# LPC13Uxx register map
File version: 1
CPU: CM3 r2p1, little endian, no MPU, no FPU, 0x3 interrupt priority bits, 0x0 interrupts
Registers are 32-bit, read-write, reset 0x0 unless marked. A register's access mark holds for its fields unless they carry their own. Offsets are from the block's base; [hi:lo] are bit positions; {n}, {i} and the like mark numbered series; 'fields as' and 'values as' point back to an identical list.

## RITIMER — Repetitive Interrupt Timer (RI timer)
Base 0x40064000
0x00 COMPVAL reset 0xFFFFFFFF — Compare value LSB register. Holds the 32 LSBs of the compare value.
  [31:0] RICOMP — Compare register. Holds the 32 LSBs of the compare value which is compared to the counter.
0x04 MASK — Mask LSB register. This register holds the 32 LSB s of the mask value. A one written to any bit will force a compare on the corresponding bit of the counter and compare register.
  [31:0] RIMASK — Mask register. This register holds the 32 LSBs of the mask value. A one written to any bit overrides the result of the comparison for the corresponding bit of the counter and compare register (causes the comparison of the register bits to be always true).
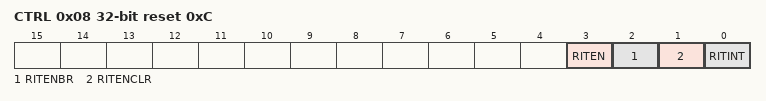
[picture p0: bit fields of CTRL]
0x08 CTRL reset 0xC — Control register.
  [3] RITEN — Timer enable.
    1=TIMER_ENABLED (Timer enabled. This can be overruled by a debug halt if enabled in bit 2.); 0=TIMER_DISABLED_
  [2] RITENBR — Timer enable for debug
    1=HALT_ON_DEBUG (The timer is halted when the processor is halted for debugging.); 0=NO_EFFECT_ON_DEBUG (Debug has no effect on the timer operation.)
  [1] RITENCLR — Timer enable clear
    1=CLEAR_ON_O (The timer will be cleared to 0 whenever the counter value equals the masked compare value specified by the contents of COMPVAL/COMPVAL_H and MASK/MASK_H registers. This will occur on the same clock that sets the interrupt flag.); 0=NOT_CLEAR_ON_0 (The timer will not be cleared to 0.)
  [0] RITINT — Interrupt flag
    1=MASK (This bit is set to 1 by hardware whenever the counter value equals the masked compare value specified by the contents of RICOMPVAL and RIMASK registers. Writing a 1 to this bit will clear it to 0. Writing a 0 has no effect.); 0=NO_MASK (The counter value does not equal the masked compare value.)
0x0C COUNTER — Counter LSB register. 32 LSBs of the counter.
  [31:0] RICOUNTER — 32 LSBs of the up counter. Counts continuously unless RITEN bit in CTRL register is cleared or debug mode is entered (if enabled by the RITNEBR bit in RICTRL). Can be loaded to any value in software.
0x10 COMPVAL_H reset 0xFFFF — Compare value MSB register. Holds the 16 MSBs of the compare value.
  [15:0] RICOMP — Compare value MSB register. Holds the 16 MSBs of the compare value which is compared to the counter.
0x14 MASK_H — Mask MSB register. This register holds the 16 MSBs of the mask value. A one written to any bit will force a compare on the corresponding bit of the counter and compare register.
  [15:0] RIMASK — Mask register. This register holds the 16 MSBs of the mask value. A one written to any bit overrides the result of the comparison for the corresponding bit of the counter and compare register (causes the comparison of the register bits to be always true).
0x18 COUNTER_H — Counter MSB register. 16 MSBs of the counter.
  [15:0] RICOUNTER — 16 LSBs of the up counter. Counts continuously unless RITEN bit in RICTRL register is cleared or debug mode is entered (if enabled by the RITNEBR bit in RICTRL). Can be loaded to any value in software.

## GPIO_PORT
Base 0x50000000
{0x0+i} B[{i}] 8-bit (i=0..63) — Byte pin registers port 0/1; pins PIO0/1_0 to PIO0/1_31
  [0] PBYTE — Read: state of the pin P0/1_n, regardless of direction, masking, or alternate function, except that pins configured as analog I/O always read as 0. Write: loads the pin's output bit.
{0x1000+4i} W[{i}] (i=0..63) — Word pin registers port 0/1
  [31:0] PWORD — Read 0: pin is LOW. Write 0: clear output bit. Read 0xFFFF FFFF: pin is HIGH. Write any value 0x0000 0001 to 0xFFFF FFFF: set output bit. Only 0 or 0xFFFF FFFF can be read. Writing any value other than 0 will set the output bit.
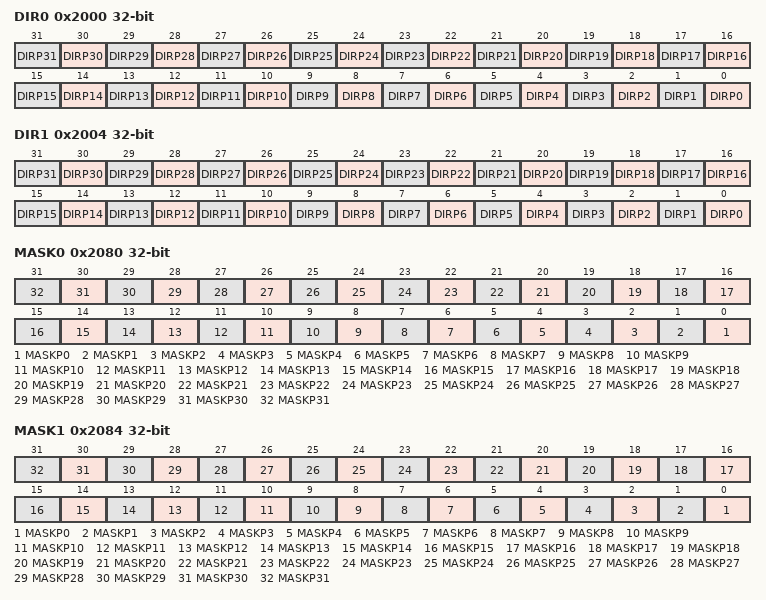
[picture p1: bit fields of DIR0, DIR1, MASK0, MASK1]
0x2000 DIR0 — Direction registers port 0/1
  [n] DIRP{n} (n=0..31) — Selects pin direction for pin P0/1_n (bit 0 = P0/1_0, bit 1 = P0_1, ..., bit 31 = P0/1_31). 0 = input. 1 = output.
0x2004 DIR1 — Direction registers port 0/1
  fields as DIR0
0x2080 MASK0 — Mask register port 0/1
  [n] MASKP{n} (n=0..31) — Controls which bits corresponding to P0/1_n are active in the P0/1 PIN register (bit 0 = P0/1_0, bit 1 = P0/1_1, ..., bit 31 = P0/1_31). 0 = Read MPORT: pin state; write MPORT: load output bit. 1 = Read MPORT: 0; write MPORT: output bit not affected.
0x2084 MASK1 — Mask register port 0/1
  fields as MASK0
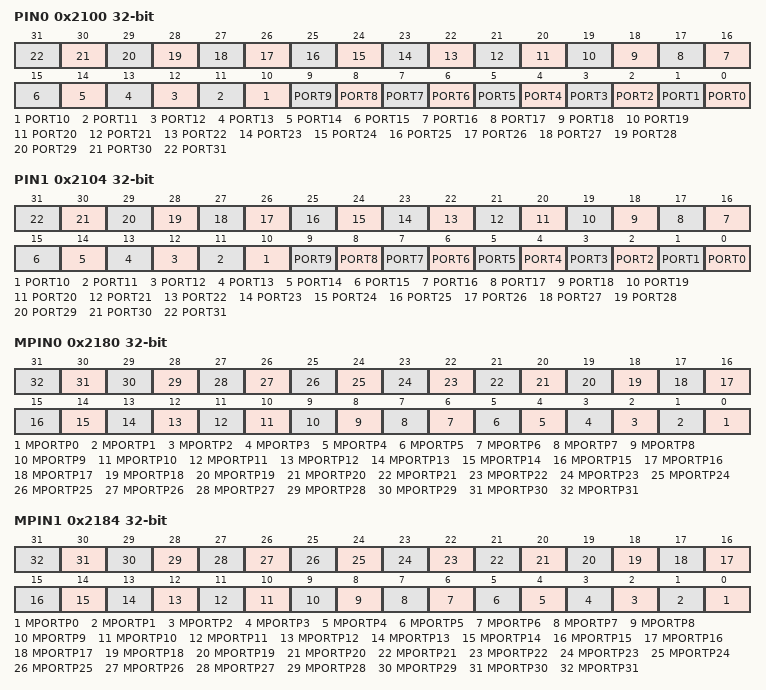
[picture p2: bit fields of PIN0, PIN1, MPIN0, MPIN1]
0x2100 PIN0 — Portpin register port 0
  [n] PORT{n} (n=0..31) — Reads pin states or loads output bits (bit 0 = P0/1_0, bit 1 = P0/1_1, ..., bit 31 = P0/1_31). 0 = Read: pin is low; write: clear output bit. 1 = Read: pin is high; write: set output bit.
0x2104 PIN1 — Portpin register port 0
  fields as PIN0
0x2180 MPIN0 — Masked port register port 0/1
  [n] MPORTP{n} (n=0..31) — Masked port register (bit 0 = P0/1_0, bit 1 = P0/1_1, ..., bit 31 = P0/1_31). 0 = Read: pin is LOW and/or the corresponding bit in the MASK register is 1; write: clear output bit if the corresponding bit in the MASK register is 0. 1 = Read: pin is HIGH and the corresponding bit in the MASK register is 0; write: set output bit if the corresponding bit in the MASK register is 0.
0x2184 MPIN1 — Masked port register port 0/1
  fields as MPIN0
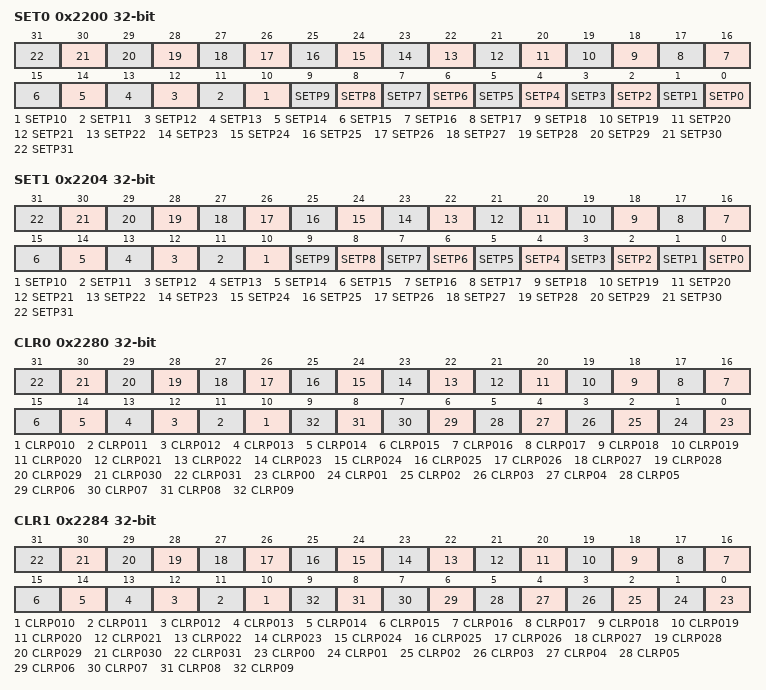
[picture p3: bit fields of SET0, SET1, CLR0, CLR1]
0x2200 SET0 — Write: Set register for port 0/1 Read: output bits for port 0/1
  [n] SETP{n} (n=0..31) — Read or set output bits. 0 = Read: output bit: write: no operation. 1 = Read: output bit; write: set output bit.
0x2204 SET1 — Write: Set register for port 0/1 Read: output bits for port 0/1
  fields as SET0
0x2280 CLR0 wo reset not defined — Clear port 0/1
  [n] CLRP{n:03} (n=10..31) — Clear output bits: 0 = No operation. 1 = Clear output bit.
  [n] CLRP{n:02} (n=0..9) — Clear output bits: 0 = No operation. 1 = Clear output bit.
0x2284 CLR1 wo reset not defined — Clear port 0/1
  fields as CLR0
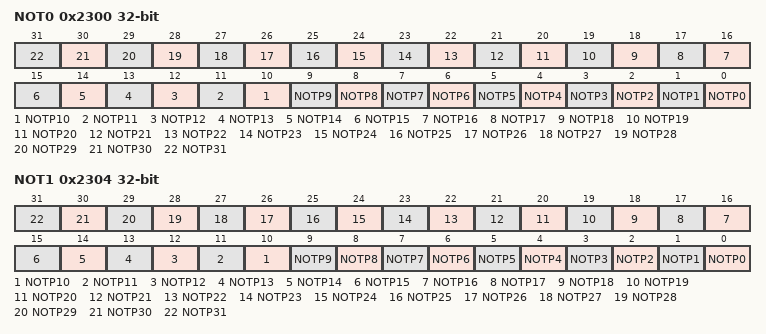
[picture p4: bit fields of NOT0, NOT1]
0x2300 NOT0 wo reset not defined — Toggle port 0/1
  [n] NOTP{n} (n=0..31) — Toggle output bits: 0 = no operation. 1 = Toggle output bit.
0x2304 NOT1 wo reset not defined — Toggle port 0/1
  fields as NOT0
